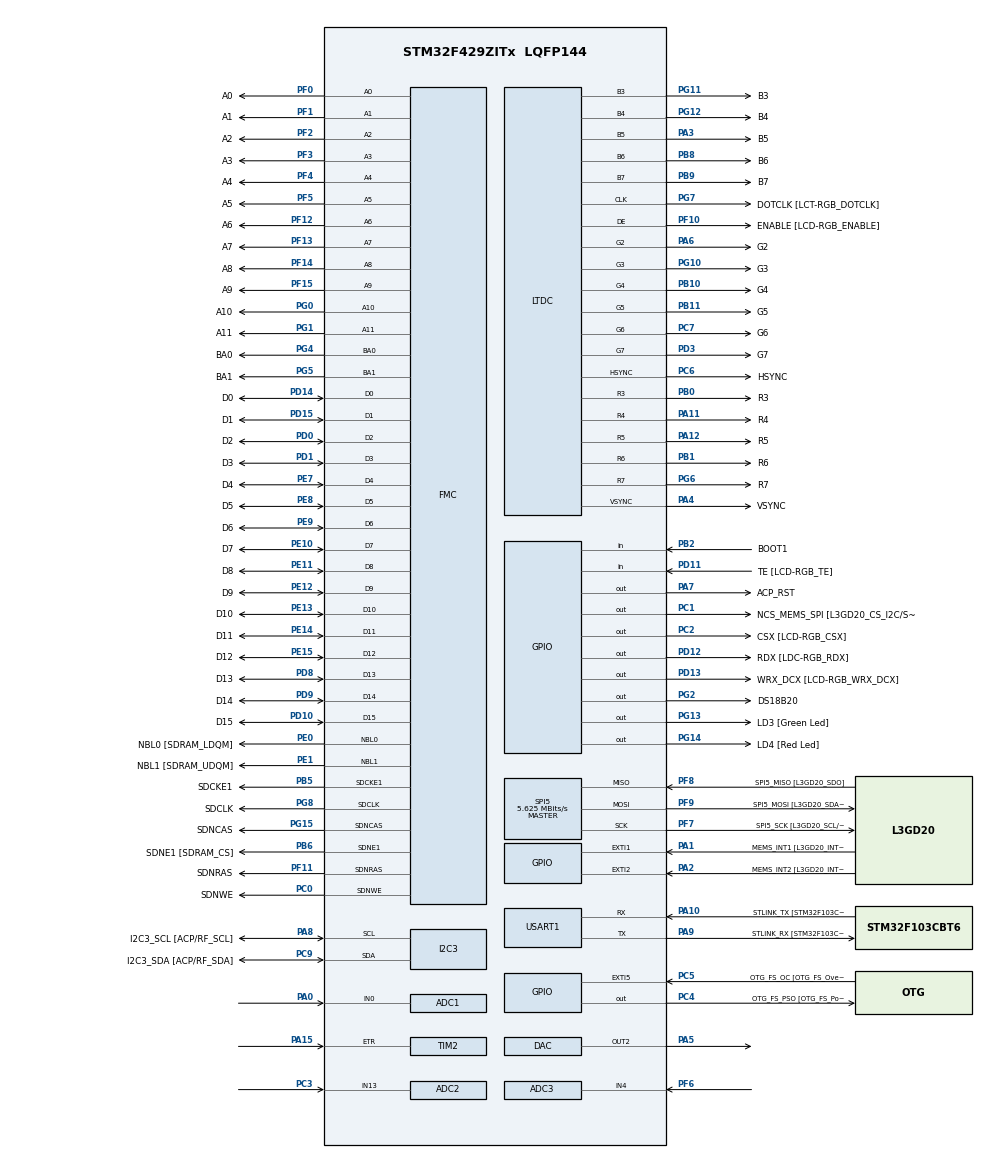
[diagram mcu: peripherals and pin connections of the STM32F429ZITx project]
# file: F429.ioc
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ADC1.Channel-4\#ChannelRegularConversion=ADC_CHANNEL_0
ADC1.ContinuousConvMode=ENABLE
ADC1.Mode=ADC_DUALMODE_REGSIMULT
ADC1.NbrOfConversionFlag=1
ADC1.Rank-4\#ChannelRegularConversion=1
ADC1.SamplingTime-4\#ChannelRegularConversion=ADC_SAMPLETIME_3CYCLES
ADC1.master=1
ADC2.Channel-0\#ChannelRegularConversion=ADC_CHANNEL_13
ADC2.DMAAccessMode=ADC_DMAACCESSMODE_2
ADC2.Mode=ADC_DUALMODE_REGSIMULT
ADC2.NbrOfConversionFlag=1
ADC2.Rank-0\#ChannelRegularConversion=1
ADC2.SamplingTime-0\#ChannelRegularConversion=ADC_SAMPLETIME_3CYCLES
ADC3.Channel-1\#ChannelRegularConversion=ADC_CHANNEL_4
ADC3.DMAAccessMode=ADC_DMAACCESSMODE_2
ADC3.Mode=ADC_DUALMODE_REGSIMULT
ADC3.NbrOfConversionFlag=1
ADC3.Rank-1\#ChannelRegularConversion=1
ADC3.SamplingTime-1\#ChannelRegularConversion=ADC_SAMPLETIME_3CYCLES
DAC.DAC_Trigger2=DAC_TRIGGER_T7_TRGO
Dma.ADC1.1.Direction=DMA_PERIPH_TO_MEMORY
Dma.ADC1.1.FIFOMode=DMA_FIFOMODE_ENABLE
Dma.ADC1.1.FIFOThreshold=DMA_FIFO_THRESHOLD_3QUARTERSFULL
Dma.ADC1.1.Instance=DMA2_Stream0
Dma.ADC1.1.MemBurst=DMA_MBURST_SINGLE
Dma.ADC1.1.MemDataAlignment=DMA_MDATAALIGN_HALFWORD
Dma.ADC1.1.MemInc=DMA_MINC_ENABLE
Dma.ADC1.1.Mode=DMA_NORMAL
Dma.ADC1.1.PeriphBurst=DMA_PBURST_SINGLE
Dma.ADC1.1.PeriphDataAlignment=DMA_PDATAALIGN_HALFWORD
Dma.ADC1.1.PeriphInc=DMA_PINC_DISABLE
Dma.ADC1.1.Priority=DMA_PRIORITY_LOW
Dma.DAC2.0.Direction=DMA_MEMORY_TO_PERIPH
Dma.DAC2.0.FIFOMode=DMA_FIFOMODE_ENABLE
Dma.DAC2.0.FIFOThreshold=DMA_FIFO_THRESHOLD_3QUARTERSFULL
Dma.DAC2.0.Instance=DMA1_Stream6
Dma.DAC2.0.MemBurst=DMA_MBURST_SINGLE
Dma.DAC2.0.MemDataAlignment=DMA_MDATAALIGN_HALFWORD
Dma.DAC2.0.MemInc=DMA_MINC_ENABLE
Dma.DAC2.0.Mode=DMA_CIRCULAR
Dma.DAC2.0.PeriphBurst=DMA_PBURST_SINGLE
Dma.DAC2.0.PeriphDataAlignment=DMA_PDATAALIGN_HALFWORD
Dma.DAC2.0.PeriphInc=DMA_PINC_DISABLE
Dma.DAC2.0.Priority=DMA_PRIORITY_LOW
Dma.Request0=DAC2
Dma.Request1=ADC1
FMC.CASLatency1=FMC_SDRAM_CAS_LATENCY_3
FMC.ExitSelfRefreshDelay1=7
FMC.LoadToActiveDelay1=2
FMC.RCDDelay1=2
FMC.RPDelay1=2
FMC.RPDelay2=2
FMC.ReadBurst1=FMC_SDRAM_RBURST_DISABLE
FMC.ReadPipeDelay1=FMC_SDRAM_RPIPE_DELAY_1
FMC.ReadPipeDelay2=FMC_SDRAM_RPIPE_DELAY_1
FMC.RowCycleDelay1=7
FMC.RowCycleDelay2=7
FMC.SDClockPeriod1=FMC_SDRAM_CLOCK_PERIOD_2
FMC.SDClockPeriod2=FMC_SDRAM_CLOCK_PERIOD_2
FMC.SelfRefreshTime1=4
FMC.WriteRecoveryTime1=3
FREERTOS.Queues01=queFrame,1,uint16_t,0,Dynamic,NULL,NULL;queFreqCount,1,uint32_t,0,Dynamic,NULL,NULL;queTouch,1,uint16_t,0,Dynamic,NULL,NULL;queInfo,16,uint32_t,0,Dynamic,NULL,NULL
FREERTOS.Tasks01=tskIdel,-2,128,fnIdel,Default,NULL,Dynamic,NULL,NULL;tskDisplay,0,1024,fnDisplay,Default,NULL,Dynamic,NULL,NULL;tskTemperature,-2,128,fnTemperature,Default,NULL,Dynamic,NULL,NULL;tskTouch,1,128,fnTouch,Default,NULL,Dynamic,NULL,NULL;tskDAC,-1,256,fnDAC,Default,NULL,Dynamic,NULL,NULL;tskFFT,2,4096,fnFFT,Default,NULL,Dynamic,NULL,NULL
FREERTOS.Timers01=timKeyDown,cbKeyDown,osTimerOnce,Default,NULL,Dynamic,NULL
FREERTOS.configCHECK_FOR_STACK_OVERFLOW=2
FREERTOS.configTOTAL_HEAP_SIZE=128000
FREERTOS.configUSE_APPLICATION_TASK_TAG=1
FREERTOS.configUSE_COUNTING_SEMAPHORES=1
FREERTOS.configUSE_IDLE_HOOK=1
FREERTOS.configUSE_MALLOC_FAILED_HOOK=1
FREERTOS.configUSE_RECURSIVE_MUTEXES=1
FREERTOS.configUSE_TIMERS=1
LTDC.ActiveH=320
LTDC.ActiveW=240
LTDC.Alpha_L0=255
LTDC.BlendingFactor1_L0=LTDC_BLENDING_FACTOR1_PAxCA
LTDC.BlendingFactor2_L0=LTDC_BLENDING_FACTOR2_PAxCA
LTDC.FBStartAdress_L0=0xD0000000
LTDC.HBP=20
LTDC.HFP=10
LTDC.HSync=10
LTDC.ImageHeight_L0=320
LTDC.ImageWidth_L0=240
LTDC.Layers=0
LTDC.PixelFormat_L0=LTDC_PIXEL_FORMAT_RGB565
LTDC.VFP=4
LTDC.VSync=2
LTDC.WindowX1_L0=240
LTDC.WindowY1_L0=320
Mcu.Family=STM32F4
Mcu.Name=STM32F429ZITx
Mcu.Package=LQFP144
NVIC.DMA1_Stream6_IRQn=true\:5\:0\:false\:false\:true\:true\:false\:true
NVIC.DMA2D_IRQn=true\:5\:0\:true\:false\:true\:true\:true\:true
NVIC.DMA2_Stream0_IRQn=true\:5\:0\:false\:false\:true\:true\:false\:true
NVIC.LTDC_IRQn=true\:5\:0\:true\:false\:true\:true\:true\:true
NVIC.PriorityGroup=NVIC_PRIORITYGROUP_4
NVIC.TIM1_UP_TIM10_IRQn=true\:5\:0\:false\:false\:true\:true\:true\:true
NVIC.TIM4_IRQn=true\:5\:0\:false\:false\:true\:true\:true\:true
NVIC.TIM5_IRQn=true\:5\:0\:false\:false\:true\:true\:true\:true
NVIC.TIM6_DAC_IRQn=true\:0\:0\:false\:false\:true\:false\:false\:true
NVIC.TimeBase=TIM6_DAC_IRQn
NVIC.TimeBaseIP=TIM6
PA0/WKUP.Signal=ADCx_IN0
PA1.GPIO_Label=MEMS_INT1 [L3GD20_INT1]
PA1.GPIO_ModeDefaultEXTI=GPIO_MODE_EVT_RISING
PA1.GPIO_PuPd=GPIO_NOPULL
PA1.Signal=GPXTI1
PA10.GPIO_Label=STLINK_TX [STM32F103CBT6_PA2]
PA10.Mode=Asynchronous
PA10.Signal=USART1_RX
PA11.GPIO_Label=R4
PA11.GPIO_Mode=GPIO_MODE_AF_PP
PA11.GPIO_PuPd=GPIO_NOPULL
PA11.GPIO_Speed=GPIO_SPEED_FREQ_LOW
PA11.Mode=RGB565
PA11.Signal=LTDC_R4
PA12.GPIO_Label=R5
PA12.GPIO_Mode=GPIO_MODE_AF_PP
PA12.GPIO_PuPd=GPIO_NOPULL
PA12.GPIO_Speed=GPIO_SPEED_FREQ_LOW
PA12.Mode=RGB565
PA12.Signal=LTDC_R5
PA13.GPIO_Label=SWDIO
PA13.Mode=Trace_Asynchronous_SW
PA13.Signal=SYS_JTMS-SWDIO
PA14.GPIO_Label=SWCLK
PA14.Mode=Trace_Asynchronous_SW
PA14.Signal=SYS_JTCK-SWCLK
PA15.Signal=S_TIM2_CH1_ETR
PA2.GPIO_Label=MEMS_INT2 [L3GD20_INT2]
PA2.GPIO_ModeDefaultEXTI=GPIO_MODE_EVT_RISING
PA2.GPIO_PuPd=GPIO_NOPULL
PA2.Signal=GPXTI2
PA3.GPIO_Label=B5
PA3.GPIO_Mode=GPIO_MODE_AF_PP
PA3.GPIO_PuPd=GPIO_NOPULL
PA3.GPIO_Speed=GPIO_SPEED_FREQ_LOW
PA3.Mode=RGB565
PA3.Signal=LTDC_B5
PA4.GPIO_Label=VSYNC
PA4.GPIO_Mode=GPIO_MODE_AF_PP
PA4.GPIO_PuPd=GPIO_NOPULL
PA4.GPIO_Speed=GPIO_SPEED_FREQ_LOW
PA4.Mode=RGB565
PA4.Signal=LTDC_VSYNC
PA5.Signal=COMP_DAC2_group
PA6.GPIO_Label=G2
PA6.GPIO_Mode=GPIO_MODE_AF_PP
PA6.GPIO_PuPd=GPIO_NOPULL
PA6.GPIO_Speed=GPIO_SPEED_FREQ_LOW
PA6.Mode=RGB565
PA6.Signal=LTDC_G2
PA7.GPIO_Label=ACP_RST
PA7.GPIO_Mode=GPIO_MODE_OUTPUT_PP
PA7.GPIO_PuPd=GPIO_NOPULL
PA7.GPIO_Speed=GPIO_SPEED_FREQ_LOW
PA7.Signal=GPIO_Output
PA8.GPIO_Label=I2C3_SCL [ACP/RF_SCL]
PA8.GPIO_Mode=GPIO_MODE_AF_OD
PA8.GPIO_PuPd=GPIO_NOPULL
PA8.GPIO_Speed=GPIO_SPEED_FREQ_LOW
PA8.Mode=I2C
PA8.Signal=I2C3_SCL
PA9.GPIO_Label=STLINK_RX [STM32F103CBT6_PA3]
PA9.Mode=Asynchronous
PA9.Signal=USART1_TX
PB0.GPIO_Label=R3
PB0.GPIO_Mode=GPIO_MODE_AF_PP
PB0.GPIO_PuPd=GPIO_NOPULL
PB0.GPIO_Speed=GPIO_SPEED_FREQ_LOW
PB0.Mode=RGB565
PB0.Signal=LTDC_R3
PB1.GPIO_Label=R6
PB1.GPIO_Mode=GPIO_MODE_AF_PP
PB1.GPIO_PuPd=GPIO_NOPULL
PB1.GPIO_Speed=GPIO_SPEED_FREQ_LOW
PB1.Mode=RGB565
PB1.Signal=LTDC_R6
PB10.GPIO_Label=G4
PB10.GPIO_Mode=GPIO_MODE_AF_PP
PB10.GPIO_PuPd=GPIO_NOPULL
PB10.GPIO_Speed=GPIO_SPEED_FREQ_LOW
PB10.Mode=RGB565
PB10.Signal=LTDC_G4
PB11.GPIO_Label=G5
PB11.GPIO_Mode=GPIO_MODE_AF_PP
PB11.GPIO_PuPd=GPIO_NOPULL
PB11.GPIO_Speed=GPIO_SPEED_FREQ_LOW
PB11.Mode=RGB565
PB11.Signal=LTDC_G5
PB2/BOOT1.GPIO_Label=BOOT1
PB2/BOOT1.GPIO_Mode=GPIO_MODE_INPUT
PB2/BOOT1.GPIO_PuPd=GPIO_NOPULL
PB2/BOOT1.Signal=GPIO_Input
PB3.Mode=Trace_Asynchronous_SW
PB3.Signal=SYS_JTDO-SWO
PB5.GPIO_Label=SDCKE1
PB5.GPIO_Mode=GPIO_MODE_AF_PP
PB5.GPIO_PuPd=GPIO_NOPULL
PB5.GPIO_Speed=GPIO_SPEED_FREQ_VERY_HIGH
PB5.Mode=SdramChipSelect2_1
PB5.Signal=FMC_SDCKE1
PB6.GPIO_Label=SDNE1 [SDRAM_CS]
PB6.GPIO_Mode=GPIO_MODE_AF_PP
PB6.GPIO_PuPd=GPIO_NOPULL
PB6.GPIO_Speed=GPIO_SPEED_FREQ_VERY_HIGH
PB6.Mode=SdramChipSelect2_1
PB6.Signal=FMC_SDNE1
PB8.GPIO_Label=B6
PB8.GPIO_Mode=GPIO_MODE_AF_PP
PB8.GPIO_PuPd=GPIO_NOPULL
PB8.GPIO_Speed=GPIO_SPEED_FREQ_LOW
PB8.Mode=RGB565
PB8.Signal=LTDC_B6
PB9.GPIO_Label=B7
PB9.GPIO_Mode=GPIO_MODE_AF_PP
PB9.GPIO_PuPd=GPIO_NOPULL
PB9.GPIO_Speed=GPIO_SPEED_FREQ_LOW
PB9.Mode=RGB565
PB9.Signal=LTDC_B7
PC0.GPIO_Label=SDNWE
PC0.GPIO_Mode=GPIO_MODE_AF_PP
PC0.GPIO_PuPd=GPIO_NOPULL
PC0.GPIO_Speed=GPIO_SPEED_FREQ_VERY_HIGH
PC0.Signal=FMC_SDNWE
PC1.GPIO_Label=NCS_MEMS_SPI [L3GD20_CS_I2C/SPI]
PC1.GPIO_Mode=GPIO_MODE_OUTPUT_PP
PC1.GPIO_PuPd=GPIO_NOPULL
PC1.GPIO_Speed=GPIO_SPEED_FREQ_LOW
PC1.Signal=GPIO_Output
PC10.GPIO_Label=R2
PC10.GPIO_Mode=GPIO_MODE_AF_PP
PC10.GPIO_PuPd=GPIO_NOPULL
PC10.GPIO_Speed=GPIO_SPEED_FREQ_LOW
PC10.Signal=LTDC_R2
PC2.GPIO_Label=CSX [LCD-RGB_CSX]
PC2.GPIO_Mode=GPIO_MODE_OUTPUT_PP
PC2.GPIO_PuPd=GPIO_NOPULL
PC2.GPIO_Speed=GPIO_SPEED_FREQ_LOW
PC2.Signal=GPIO_Output
PC3.Signal=ADCx_IN13
PC4.GPIO_Label=OTG_FS_PSO [OTG_FS_PowerSwitchOn]
PC4.GPIO_Mode=GPIO_MODE_OUTPUT_PP
PC4.GPIO_PuPd=GPIO_NOPULL
PC4.GPIO_Speed=GPIO_SPEED_FREQ_LOW
PC4.Signal=GPIO_Output
PC5.GPIO_Label=OTG_FS_OC [OTG_FS_OverCurrent]
PC5.GPIO_ModeDefaultEXTI=GPIO_MODE_EVT_RISING
PC5.Signal=GPXTI5
PC6.GPIO_Label=HSYNC
PC6.GPIO_Mode=GPIO_MODE_AF_PP
PC6.GPIO_PuPd=GPIO_NOPULL
PC6.GPIO_Speed=GPIO_SPEED_FREQ_LOW
PC6.Mode=RGB565
PC6.Signal=LTDC_HSYNC
PC7.GPIO_Label=G6
PC7.GPIO_Mode=GPIO_MODE_AF_PP
PC7.GPIO_PuPd=GPIO_NOPULL
PC7.GPIO_Speed=GPIO_SPEED_FREQ_LOW
PC7.Mode=RGB565
PC7.Signal=LTDC_G6
PC9.GPIO_Label=I2C3_SDA [ACP/RF_SDA]
PC9.GPIO_Mode=GPIO_MODE_AF_OD
PC9.GPIO_PuPd=GPIO_NOPULL
PC9.GPIO_Speed=GPIO_SPEED_FREQ_LOW
PC9.Mode=I2C
PC9.Signal=I2C3_SDA
PD0.GPIO_Label=D2
PD0.GPIO_Mode=GPIO_MODE_AF_PP
PD0.GPIO_PuPd=GPIO_NOPULL
PD0.GPIO_Speed=GPIO_SPEED_FREQ_VERY_HIGH
PD0.Signal=FMC_D2_DA2
PD1.GPIO_Label=D3
PD1.GPIO_Mode=GPIO_MODE_AF_PP
PD1.GPIO_PuPd=GPIO_NOPULL
PD1.GPIO_Speed=GPIO_SPEED_FREQ_VERY_HIGH
PD1.Signal=FMC_D3_DA3
PD10.GPIO_Label=D15
PD10.GPIO_Mode=GPIO_MODE_AF_PP
PD10.GPIO_PuPd=GPIO_NOPULL
PD10.GPIO_Speed=GPIO_SPEED_FREQ_VERY_HIGH
PD10.Signal=FMC_D15_DA15
PD11.GPIO_Label=TE [LCD-RGB_TE]
PD11.GPIO_Mode=GPIO_MODE_INPUT
PD11.GPIO_PuPd=GPIO_NOPULL
PD11.Signal=GPIO_Input
PD12.GPIO_Label=RDX [LDC-RGB_RDX]
PD12.GPIO_Mode=GPIO_MODE_OUTPUT_PP
PD12.GPIO_PuPd=GPIO_NOPULL
PD12.GPIO_Speed=GPIO_SPEED_FREQ_LOW
PD12.Signal=GPIO_Output
PD13.GPIO_Label=WRX_DCX [LCD-RGB_WRX_DCX]
PD13.GPIO_Mode=GPIO_MODE_OUTPUT_PP
PD13.GPIO_PuPd=GPIO_NOPULL
PD13.GPIO_Speed=GPIO_SPEED_FREQ_LOW
PD13.Signal=GPIO_Output
PD14.GPIO_Label=D0
PD14.GPIO_Mode=GPIO_MODE_AF_PP
PD14.GPIO_PuPd=GPIO_NOPULL
PD14.GPIO_Speed=GPIO_SPEED_FREQ_VERY_HIGH
PD14.Signal=FMC_D0_DA0
PD15.GPIO_Label=D1
PD15.GPIO_Mode=GPIO_MODE_AF_PP
PD15.GPIO_PuPd=GPIO_NOPULL
PD15.GPIO_Speed=GPIO_SPEED_FREQ_VERY_HIGH
PD15.Signal=FMC_D1_DA1
PD3.GPIO_Label=G7
PD3.GPIO_Mode=GPIO_MODE_AF_PP
PD3.GPIO_PuPd=GPIO_NOPULL
PD3.GPIO_Speed=GPIO_SPEED_FREQ_LOW
PD3.Mode=RGB565
PD3.Signal=LTDC_G7
PD6.GPIO_Label=B2
PD6.GPIO_Mode=GPIO_MODE_AF_PP
PD6.GPIO_PuPd=GPIO_NOPULL
PD6.GPIO_Speed=GPIO_SPEED_FREQ_LOW
PD6.Signal=LTDC_B2
PD8.GPIO_Label=D13
PD8.GPIO_Mode=GPIO_MODE_AF_PP
PD8.GPIO_PuPd=GPIO_NOPULL
PD8.GPIO_Speed=GPIO_SPEED_FREQ_VERY_HIGH
PD8.Signal=FMC_D13_DA13
PD9.GPIO_Label=D14
PD9.GPIO_Mode=GPIO_MODE_AF_PP
PD9.GPIO_PuPd=GPIO_NOPULL
PD9.GPIO_Speed=GPIO_SPEED_FREQ_VERY_HIGH
PD9.Signal=FMC_D14_DA14
PE0.GPIO_Label=NBL0 [SDRAM_LDQM]
PE0.GPIO_Mode=GPIO_MODE_AF_PP
PE0.GPIO_PuPd=GPIO_NOPULL
PE0.GPIO_Speed=GPIO_SPEED_FREQ_VERY_HIGH
PE0.Signal=FMC_NBL0
PE1.GPIO_Label=NBL1 [SDRAM_UDQM]
PE1.GPIO_Mode=GPIO_MODE_AF_PP
PE1.GPIO_PuPd=GPIO_NOPULL
PE1.GPIO_Speed=GPIO_SPEED_FREQ_VERY_HIGH
PE1.Signal=FMC_NBL1
PE10.GPIO_Label=D7
PE10.GPIO_Mode=GPIO_MODE_AF_PP
PE10.GPIO_PuPd=GPIO_NOPULL
PE10.GPIO_Speed=GPIO_SPEED_FREQ_VERY_HIGH
PE10.Signal=FMC_D7_DA7
PE11.GPIO_Label=D8
PE11.GPIO_Mode=GPIO_MODE_AF_PP
PE11.GPIO_PuPd=GPIO_NOPULL
PE11.GPIO_Speed=GPIO_SPEED_FREQ_VERY_HIGH
PE11.Signal=FMC_D8_DA8
PE12.GPIO_Label=D9
PE12.GPIO_Mode=GPIO_MODE_AF_PP
PE12.GPIO_PuPd=GPIO_NOPULL
PE12.GPIO_Speed=GPIO_SPEED_FREQ_VERY_HIGH
PE12.Signal=FMC_D9_DA9
PE13.GPIO_Label=D10
PE13.GPIO_Mode=GPIO_MODE_AF_PP
PE13.GPIO_PuPd=GPIO_NOPULL
PE13.GPIO_Speed=GPIO_SPEED_FREQ_VERY_HIGH
PE13.Signal=FMC_D10_DA10
PE14.GPIO_Label=D11
PE14.GPIO_Mode=GPIO_MODE_AF_PP
PE14.GPIO_PuPd=GPIO_NOPULL
PE14.GPIO_Speed=GPIO_SPEED_FREQ_VERY_HIGH
PE14.Signal=FMC_D11_DA11
PE15.GPIO_Label=D12
PE15.GPIO_Mode=GPIO_MODE_AF_PP
PE15.GPIO_PuPd=GPIO_NOPULL
PE15.GPIO_Speed=GPIO_SPEED_FREQ_VERY_HIGH
PE15.Signal=FMC_D12_DA12
PE7.GPIO_Label=D4
PE7.GPIO_Mode=GPIO_MODE_AF_PP
PE7.GPIO_PuPd=GPIO_NOPULL
PE7.GPIO_Speed=GPIO_SPEED_FREQ_VERY_HIGH
PE7.Signal=FMC_D4_DA4
PE8.GPIO_Label=D5
PE8.GPIO_Mode=GPIO_MODE_AF_PP
PE8.GPIO_PuPd=GPIO_NOPULL
PE8.GPIO_Speed=GPIO_SPEED_FREQ_VERY_HIGH
PE8.Signal=FMC_D5_DA5
PE9.GPIO_Label=D6
PE9.GPIO_Mode=GPIO_MODE_AF_PP
PE9.GPIO_PuPd=GPIO_NOPULL
PE9.GPIO_Speed=GPIO_SPEED_FREQ_VERY_HIGH
PE9.Signal=FMC_D6_DA6
PF0.GPIO_Label=A0
PF0.GPIO_Mode=GPIO_MODE_AF_PP
PF0.GPIO_PuPd=GPIO_NOPULL
PF0.GPIO_Speed=GPIO_SPEED_FREQ_VERY_HIGH
PF0.Signal=FMC_A0
PF1.GPIO_Label=A1
PF1.GPIO_Mode=GPIO_MODE_AF_PP
PF1.GPIO_PuPd=GPIO_NOPULL
PF1.GPIO_Speed=GPIO_SPEED_FREQ_VERY_HIGH
PF1.Signal=FMC_A1
PF10.GPIO_Label=ENABLE [LCD-RGB_ENABLE]
PF10.GPIO_Mode=GPIO_MODE_AF_PP
PF10.GPIO_PuPd=GPIO_NOPULL
PF10.GPIO_Speed=GPIO_SPEED_FREQ_LOW
PF10.Mode=RGB565
PF10.Signal=LTDC_DE
PF11.GPIO_Label=SDNRAS
PF11.GPIO_Mode=GPIO_MODE_AF_PP
PF11.GPIO_PuPd=GPIO_NOPULL
PF11.GPIO_Speed=GPIO_SPEED_FREQ_VERY_HIGH
PF11.Signal=FMC_SDNRAS
PF12.GPIO_Label=A6
PF12.GPIO_Mode=GPIO_MODE_AF_PP
PF12.GPIO_PuPd=GPIO_NOPULL
PF12.GPIO_Speed=GPIO_SPEED_FREQ_VERY_HIGH
PF12.Signal=FMC_A6
PF13.GPIO_Label=A7
PF13.GPIO_Mode=GPIO_MODE_AF_PP
PF13.GPIO_PuPd=GPIO_NOPULL
PF13.GPIO_Speed=GPIO_SPEED_FREQ_VERY_HIGH
PF13.Signal=FMC_A7
PF14.GPIO_Label=A8
PF14.GPIO_Mode=GPIO_MODE_AF_PP
PF14.GPIO_PuPd=GPIO_NOPULL
PF14.GPIO_Speed=GPIO_SPEED_FREQ_VERY_HIGH
PF14.Signal=FMC_A8
PF15.GPIO_Label=A9
PF15.GPIO_Mode=GPIO_MODE_AF_PP
PF15.GPIO_PuPd=GPIO_NOPULL
PF15.GPIO_Speed=GPIO_SPEED_FREQ_VERY_HIGH
PF15.Signal=FMC_A9
PF2.GPIO_Label=A2
PF2.GPIO_Mode=GPIO_MODE_AF_PP
PF2.GPIO_PuPd=GPIO_NOPULL
PF2.GPIO_Speed=GPIO_SPEED_FREQ_VERY_HIGH
PF2.Signal=FMC_A2
PF3.GPIO_Label=A3
PF3.GPIO_Mode=GPIO_MODE_AF_PP
PF3.GPIO_PuPd=GPIO_NOPULL
PF3.GPIO_Speed=GPIO_SPEED_FREQ_VERY_HIGH
PF3.Signal=FMC_A3
PF4.GPIO_Label=A4
PF4.GPIO_Mode=GPIO_MODE_AF_PP
PF4.GPIO_PuPd=GPIO_NOPULL
PF4.GPIO_Speed=GPIO_SPEED_FREQ_VERY_HIGH
PF4.Signal=FMC_A4
PF5.GPIO_Label=A5
PF5.GPIO_Mode=GPIO_MODE_AF_PP
PF5.GPIO_PuPd=GPIO_NOPULL
PF5.GPIO_Speed=GPIO_SPEED_FREQ_VERY_HIGH
PF5.Signal=FMC_A5
PF6.Mode=IN4
PF6.Signal=ADC3_IN4
PF7.GPIO_Label=SPI5_SCK [L3GD20_SCL/SPC]
PF7.GPIO_Mode=GPIO_MODE_AF_PP
PF7.GPIO_PuPd=GPIO_NOPULL
PF7.GPIO_Speed=GPIO_SPEED_FREQ_LOW
PF7.Mode=Full_Duplex_Master
PF7.Signal=SPI5_SCK
PF8.GPIO_Label=SPI5_MISO [L3GD20_SDO]
PF8.GPIO_Mode=GPIO_MODE_AF_PP
PF8.GPIO_PuPd=GPIO_NOPULL
PF8.GPIO_Speed=GPIO_SPEED_FREQ_LOW
PF8.Mode=Full_Duplex_Master
PF8.Signal=SPI5_MISO
PF9.GPIO_Label=SPI5_MOSI [L3GD20_SDA/SDI/SDO]
PF9.GPIO_Mode=GPIO_MODE_AF_PP
PF9.GPIO_PuPd=GPIO_NOPULL
PF9.GPIO_Speed=GPIO_SPEED_FREQ_LOW
PF9.Mode=Full_Duplex_Master
PF9.Signal=SPI5_MOSI
PG0.GPIO_Label=A10
PG0.GPIO_Mode=GPIO_MODE_AF_PP
PG0.GPIO_PuPd=GPIO_NOPULL
PG0.GPIO_Speed=GPIO_SPEED_FREQ_VERY_HIGH
PG0.Signal=FMC_A10
PG1.GPIO_Label=A11
PG1.GPIO_Mode=GPIO_MODE_AF_PP
PG1.GPIO_PuPd=GPIO_NOPULL
PG1.GPIO_Speed=GPIO_SPEED_FREQ_VERY_HIGH
PG1.Signal=FMC_A11
PG10.GPIO_Label=G3
PG10.GPIO_Mode=GPIO_MODE_AF_PP
PG10.GPIO_PuPd=GPIO_NOPULL
PG10.GPIO_Speed=GPIO_SPEED_FREQ_LOW
PG10.Mode=RGB565
PG10.Signal=LTDC_G3
PG11.GPIO_Label=B3
PG11.GPIO_Mode=GPIO_MODE_AF_PP
PG11.GPIO_PuPd=GPIO_NOPULL
PG11.GPIO_Speed=GPIO_SPEED_FREQ_LOW
PG11.Mode=RGB565
PG11.Signal=LTDC_B3
PG12.GPIO_Label=B4
PG12.GPIO_Mode=GPIO_MODE_AF_PP
PG12.GPIO_PuPd=GPIO_NOPULL
PG12.GPIO_Speed=GPIO_SPEED_FREQ_LOW
PG12.Mode=RGB565
PG12.Signal=LTDC_B4
PG13.GPIO_Label=LD3 [Green Led]
PG13.GPIO_Mode=GPIO_MODE_OUTPUT_PP
PG13.GPIO_PuPd=GPIO_NOPULL
PG13.GPIO_Speed=GPIO_SPEED_FREQ_LOW
PG13.Signal=GPIO_Output
PG14.GPIO_Label=LD4 [Red Led]
PG14.GPIO_Mode=GPIO_MODE_OUTPUT_PP
PG14.GPIO_PuPd=GPIO_NOPULL
PG14.GPIO_Speed=GPIO_SPEED_FREQ_LOW
PG14.Signal=GPIO_Output
PG15.GPIO_Label=SDNCAS
PG15.GPIO_Mode=GPIO_MODE_AF_PP
PG15.GPIO_PuPd=GPIO_NOPULL
PG15.GPIO_Speed=GPIO_SPEED_FREQ_VERY_HIGH
PG15.Signal=FMC_SDNCAS
PG2.GPIO_Label=DS18B20
PG2.GPIO_PuPd=GPIO_PULLUP
PG2.Signal=GPIO_Output
PG4.GPIO_Label=BA0
PG4.GPIO_Mode=GPIO_MODE_AF_PP
PG4.GPIO_PuPd=GPIO_NOPULL
PG4.GPIO_Speed=GPIO_SPEED_FREQ_VERY_HIGH
PG4.Signal=FMC_A14_BA0
PG5.GPIO_Label=BA1
PG5.GPIO_Mode=GPIO_MODE_AF_PP
PG5.GPIO_PuPd=GPIO_NOPULL
PG5.GPIO_Speed=GPIO_SPEED_FREQ_VERY_HIGH
PG5.Signal=FMC_A15_BA1
PG6.GPIO_Label=R7
PG6.GPIO_Mode=GPIO_MODE_AF_PP
PG6.GPIO_PuPd=GPIO_NOPULL
PG6.GPIO_Speed=GPIO_SPEED_FREQ_LOW
PG6.Mode=RGB565
PG6.Signal=LTDC_R7
PG7.GPIO_Label=DOTCLK [LCT-RGB_DOTCLK]
PG7.GPIO_Mode=GPIO_MODE_AF_PP
PG7.GPIO_PuPd=GPIO_NOPULL
PG7.GPIO_Speed=GPIO_SPEED_FREQ_LOW
PG7.Mode=RGB565
PG7.Signal=LTDC_CLK
PG8.GPIO_Label=SDCLK
PG8.GPIO_Mode=GPIO_MODE_AF_PP
PG8.GPIO_PuPd=GPIO_NOPULL
PG8.GPIO_Speed=GPIO_SPEED_FREQ_VERY_HIGH
PG8.Signal=FMC_SDCLK
PH0/OSC_IN.GPIO_Label=PH0-OSC_IN
PH0/OSC_IN.Mode=HSE-External-Oscillator
PH0/OSC_IN.Signal=RCC_OSC_IN
PH1/OSC_OUT.GPIO_Label=PH1-OSC_OUT
PH1/OSC_OUT.Mode=HSE-External-Oscillator
PH1/OSC_OUT.Signal=RCC_OSC_OUT
ProjectManager.HeapSize=0x200
ProjectManager.StackSize=0x400
ProjectManager.TargetToolchain=STM32CubeIDE
RCC.48MHZClocksFreq_Value=120000000
RCC.AHBFreq_Value=180000000
RCC.APB1CLKDivider=RCC_HCLK_DIV4
RCC.APB1Freq_Value=45000000
RCC.APB1TimFreq_Value=90000000
RCC.APB2CLKDivider=RCC_HCLK_DIV2
RCC.APB2Freq_Value=90000000
RCC.APB2TimFreq_Value=180000000
RCC.CortexFreq_Value=180000000
RCC.HCLKFreq_Value=180000000
RCC.HSE_VALUE=8000000
RCC.HSI_VALUE=16000000
RCC.LSE_VALUE=32768
RCC.PLLM=4
RCC.PLLN=180
RCC.PLLQ=3
RCC.PLLSAIDivR=RCC_PLLSAIDIVR_4
RCC.PLLSAIN=60
RCC.PLLSAIR=5
RCC.PLLSourceVirtual=RCC_PLLSOURCE_HSE
RCC.SYSCLKFreq_VALUE=180000000
RCC.SYSCLKSource=RCC_SYSCLKSOURCE_PLLCLK
RCC.VCOOutputFreq_Value=360000000
SH.ADCx_IN0.0=ADC1_IN0,IN0
SH.ADCx_IN13.0=ADC2_IN13,IN13
SH.COMP_DAC2_group.0=DAC_OUT2,DAC_OUT2
SH.FMC_A0.0=FMC_A0,12b-sda1
SH.FMC_A1.0=FMC_A1,12b-sda1
SH.FMC_A10.0=FMC_A10,12b-sda1
SH.FMC_A11.0=FMC_A11,12b-sda1
SH.FMC_A14_BA0.0=FMC_BA0,FourSdramBanks1
SH.FMC_A15_BA1.0=FMC_BA1,FourSdramBanks1
SH.FMC_A2.0=FMC_A2,12b-sda1
SH.FMC_A3.0=FMC_A3,12b-sda1
SH.FMC_A4.0=FMC_A4,12b-sda1
SH.FMC_A5.0=FMC_A5,12b-sda1
SH.FMC_A6.0=FMC_A6,12b-sda1
SH.FMC_A7.0=FMC_A7,12b-sda1
SH.FMC_A8.0=FMC_A8,12b-sda1
SH.FMC_A9.0=FMC_A9,12b-sda1
SH.FMC_D0_DA0.0=FMC_D0,sd-16b-d1
SH.FMC_D10_DA10.0=FMC_D10,sd-16b-d1
SH.FMC_D11_DA11.0=FMC_D11,sd-16b-d1
SH.FMC_D12_DA12.0=FMC_D12,sd-16b-d1
SH.FMC_D13_DA13.0=FMC_D13,sd-16b-d1
SH.FMC_D14_DA14.0=FMC_D14,sd-16b-d1
SH.FMC_D15_DA15.0=FMC_D15,sd-16b-d1
SH.FMC_D1_DA1.0=FMC_D1,sd-16b-d1
SH.FMC_D2_DA2.0=FMC_D2,sd-16b-d1
SH.FMC_D3_DA3.0=FMC_D3,sd-16b-d1
SH.FMC_D4_DA4.0=FMC_D4,sd-16b-d1
SH.FMC_D5_DA5.0=FMC_D5,sd-16b-d1
SH.FMC_D6_DA6.0=FMC_D6,sd-16b-d1
SH.FMC_D7_DA7.0=FMC_D7,sd-16b-d1
SH.FMC_D8_DA8.0=FMC_D8,sd-16b-d1
SH.FMC_D9_DA9.0=FMC_D9,sd-16b-d1
SH.FMC_NBL0.0=FMC_NBL0,Sd2ByteEnable1
SH.FMC_NBL1.0=FMC_NBL1,Sd2ByteEnable1
SH.FMC_SDCLK.0=FMC_SDCLK,12b-sda1
SH.FMC_SDNCAS.0=FMC_SDNCAS,12b-sda1
SH.FMC_SDNRAS.0=FMC_SDNRAS,12b-sda1
SH.FMC_SDNWE.0=FMC_SDNWE,12b-sda1
SH.S_TIM2_CH1_ETR.0=TIM2_ETR,ClockSourceETR_Mode2
SPI5.BaudRatePrescaler=SPI_BAUDRATEPRESCALER_16
SPI5.CalculateBaudRate=5.625 MBits/s
SPI5.Direction=SPI_DIRECTION_2LINES
SPI5.Mode=SPI_MODE_MASTER
SPI5.VirtualType=VM_MASTER
TIM10.Period=29999
TIM10.Prescaler=179
TIM2.AutoReloadPreload=TIM_AUTORELOAD_PRELOAD_ENABLE
TIM2.Period=0xffffffff
TIM2.TIM_MasterOutputTrigger=TIM_TRGO_UPDATE
TIM4.AutoReloadPreload=TIM_AUTORELOAD_PRELOAD_ENABLE
TIM4.Period=39999
TIM4.Prescaler=89
TIM4.TIM_MasterOutputTrigger=TIM_TRGO_UPDATE
TIM5.AutoReloadPreload=TIM_AUTORELOAD_PRELOAD_ENABLE
TIM5.Period=9999
TIM5.Prescaler=8999
TIM5.TIM_MasterOutputTrigger=TIM_TRGO_UPDATE
TIM7.Period=89
TIM7.Prescaler=0
TIM7.TIM_MasterOutputTrigger=TIM_TRGO_UPDATE
USART1.VirtualMode=VM_ASYNC
VP_CRC_VS_CRC.Mode=CRC_Activate
VP_DMA2D_VS_DMA2D.Mode=DMA2D_Activate
VP_FREERTOS_VS_CMSIS_V1.Mode=CMSIS_V1
VP_SYS_VS_tim6.Mode=TIM6
VP_TIM10_VS_ClockSourceINT.Mode=Enable_Timer
VP_TIM1_VS_ClockSourceINT.Mode=Internal
VP_TIM4_VS_ClockSourceINT.Mode=Internal
VP_TIM5_VS_ClockSourceINT.Mode=Internal
VP_TIM7_VS_ClockSourceINT.Mode=Enable_Timer
board=STM32F429I-DISC1

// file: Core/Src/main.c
/* USER CODE BEGIN Header */
/**
  ******************************************************************************
  * @file           : main.c
  * @brief          : Main program body
  ******************************************************************************
  * @attention
  *
  * <h2><center>&copy; Copyright (c) 2020 STMicroelectronics.
  * All rights reserved.</center></h2>
  *
  * This software component is licensed by ST under Ultimate Liberty license
  * SLA0044, the "License"; You may not use this file except in compliance with
  * the License. You may obtain a copy of the License at:
  *                             www.st.com/SLA0044
  *
  ******************************************************************************
  */
/* USER CODE END Header */

#include "main.h"
#include "cmsis_os.h"
#include "adc.h"
#include "crc.h"
#include "dac.h"
#include "dma.h"
#include "dma2d.h"
#include "i2c.h"
#include "ltdc.h"
#include "spi.h"
#include "tim.h"
#include "usart.h"
#include "gpio.h"
#include "fmc.h"

/* USER CODE BEGIN Includes */
#include "../../Board/Inc/board.h"
/* USER CODE END Includes */

/* USER CODE BEGIN PV */
extern osMessageQId queTouchHandle;
/* USER CODE END PV */

void SystemClock_Config(void);
void MX_FREERTOS_Init(void);

int main(void)
{

  /* MCU Configuration--------------------------------------------------------*/

  /* Reset of all peripherals, Initializes the Flash interface and the Systick. */
  HAL_Init();

  /* Configure the system clock */
  SystemClock_Config();

  /* Initialize all configured peripherals */
  MX_GPIO_Init();
  MX_DMA_Init();
  MX_CRC_Init();
  MX_DMA2D_Init();
  MX_FMC_Init();
  MX_I2C3_Init();
  MX_LTDC_Init();
  MX_SPI5_Init();
  MX_TIM1_Init();
  MX_USART1_UART_Init();
  MX_ADC1_Init();
  MX_TIM2_Init();
  MX_TIM4_Init();
  MX_TIM5_Init();
  MX_DAC_Init();
  MX_ADC2_Init();
  MX_ADC3_Init();
  MX_TIM7_Init();
  MX_TIM10_Init();
  /* USER CODE BEGIN 2 */
  board_init(hltdc.LayerCfg[0].FBStartAdress);
  /* USER CODE END 2 */

  /* Call init function for freertos objects (in freertos.c) */
  MX_FREERTOS_Init();
  /* Start scheduler */
  osKernelStart();

  /* We should never get here as control is now taken by the scheduler */
  /* Infinite loop */
  while (1)
  {

  }
}

void SystemClock_Config(void)
{
  LL_FLASH_SetLatency(LL_FLASH_LATENCY_5);

  if(LL_FLASH_GetLatency() != LL_FLASH_LATENCY_5)
  {
  Error_Handler();
  }
  LL_PWR_SetRegulVoltageScaling(LL_PWR_REGU_VOLTAGE_SCALE1);
  LL_PWR_EnableOverDriveMode();
  LL_RCC_HSE_Enable();

   /* Wait till HSE is ready */
  while(LL_RCC_HSE_IsReady() != 1)
  {

  }
  LL_RCC_PLL_ConfigDomain_SYS(LL_RCC_PLLSOURCE_HSE, LL_RCC_PLLM_DIV_4, 180, LL_RCC_PLLP_DIV_2);
  LL_RCC_PLLSAI_ConfigDomain_LTDC(LL_RCC_PLLSOURCE_HSE, LL_RCC_PLLSAIM_DIV_4, 60, LL_RCC_PLLSAIR_DIV_5, LL_RCC_PLLSAIDIVR_DIV_4);
  LL_RCC_PLL_Enable();

   /* Wait till PLL is ready */
  while(LL_RCC_PLL_IsReady() != 1)
  {

  }
  LL_RCC_PLLSAI_Enable();

   /* Wait till PLL is ready */
  while(LL_RCC_PLLSAI_IsReady() != 1)
  {

  }
  LL_RCC_SetAHBPrescaler(LL_RCC_SYSCLK_DIV_1);
  LL_RCC_SetAPB1Prescaler(LL_RCC_APB1_DIV_4);
  LL_RCC_SetAPB2Prescaler(LL_RCC_APB2_DIV_2);
  LL_RCC_SetSysClkSource(LL_RCC_SYS_CLKSOURCE_PLL);

   /* Wait till System clock is ready */
  while(LL_RCC_GetSysClkSource() != LL_RCC_SYS_CLKSOURCE_STATUS_PLL)
  {

  }
  LL_SetSystemCoreClock(180000000);

   /* Update the time base */
  if (HAL_InitTick (TICK_INT_PRIORITY) != HAL_OK)
  {
    Error_Handler();
  };
  LL_RCC_SetTIMPrescaler(LL_RCC_TIM_PRESCALER_TWICE);
}

 /**
  * @brief  Period elapsed callback in non blocking mode
  * @note   This function is called  when TIM6 interrupt took place, inside
  * HAL_TIM_IRQHandler(). It makes a direct call to HAL_IncTick() to increment
  * a global variable "uwTick" used as application time base.
  * @param  htim : TIM handle
  * @retval None
  */
void HAL_TIM_PeriodElapsedCallback(TIM_HandleTypeDef *htim)
{
  if (htim->Instance == TIM6) {
    HAL_IncTick();
  }
  /* USER CODE BEGIN Callback 1 */
	if(htim->Instance == TIM10){
		osMessagePut(queTouchHandle, 0, 0);
		LL_TIM_ClearFlag_UPDATE(TIM10);
	}
  /* USER CODE END Callback 1 */
}

void Error_Handler(void)
{
}

/************************ (C) COPYRIGHT STMicroelectronics *****END OF FILE****/

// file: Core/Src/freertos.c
/* USER CODE BEGIN Header */
/**
 ******************************************************************************
 * File Name          : freertos.c
 * Description        : Code for freertos applications
 ******************************************************************************
 * @attention
 *
 * <h2><center>&copy; Copyright (c) 2020 STMicroelectronics.
 * All rights reserved.</center></h2>
 *
 * This software component is licensed by ST under Ultimate Liberty license
 * SLA0044, the "License"; You may not use this file except in compliance with
 * the License. You may obtain a copy of the License at:
 *                             www.st.com/SLA0044
 *
 ******************************************************************************
 */
/* USER CODE END Header */

#include "FreeRTOS.h"
#include "task.h"
#include "main.h"
#include "cmsis_os.h"

/* USER CODE BEGIN Includes */
#include "tim.h"
#include <stdio.h>
#include <stdlib.h>
#include "../../Board/Inc/board.h"
#include "../../CNSIT/Inc/GRAPHICS.h"
#include "../../CNSIT/Inc/DS18B20.h"
//#include "../../CNSIT/Font/FONT_ENHANCED_DOT_DIGITAL_16PT.h"
//const CNSITFontDescTypeDef* font = &enhancedDotDigital7_16ptDesc;
#include "../../CNSIT/Font/FONT_APPLE_][_12PT.h"
const CNSITFontDescTypeDef* font = &apple_12ptDesc;
/* USER CODE END Includes */

/* USER CODE BEGIN Variables */
__IO uint32_t freq_count;
/* USER CODE END Variables */
osThreadId tskIdelHandle;
osThreadId tskDisplayHandle;
osThreadId tskTemperatureHandle;
osThreadId tskTouchHandle;
osThreadId tskDACHandle;
osThreadId tskFFTHandle;
osMessageQId queFrameHandle;
osMessageQId queFreqCountHandle;
osMessageQId queTouchHandle;
osMessageQId queInfoHandle;
osTimerId timKeyDownHandle;

void fnIdel(void const * argument);
void fnDisplay(void const * argument);
void fnTemperature(void const * argument);
void fnTouch(void const * argument);
void fnDAC(void const * argument);
void fnFFT(void const * argument);
void cbKeyDown(void const * argument);

void MX_FREERTOS_Init(void); /* (MISRA C 2004 rule 8.1) */

/* GetIdleTaskMemory prototype (linked to static allocation support) */
void vApplicationGetIdleTaskMemory( StaticTask_t **ppxIdleTaskTCBBuffer, StackType_t **ppxIdleTaskStackBuffer, uint32_t *pulIdleTaskStackSize );

/* GetTimerTaskMemory prototype (linked to static allocation support) */
void vApplicationGetTimerTaskMemory( StaticTask_t **ppxTimerTaskTCBBuffer, StackType_t **ppxTimerTaskStackBuffer, uint32_t *pulTimerTaskStackSize );

/* Hook prototypes */
void vApplicationIdleHook(void);
void vApplicationStackOverflowHook(xTaskHandle xTask, signed char *pcTaskName);
void vApplicationMallocFailedHook(void);

/* USER CODE BEGIN 2 */
__weak void vApplicationIdleHook( void )
{
	/* vApplicationIdleHook() will only be called if configUSE_IDLE_HOOK is set
   to 1 in FreeRTOSConfig.h. It will be called on each iteration of the idle
   task. It is essential that code added to this hook function never attempts
   to block in any way (for example, call xQueueReceive() with a block time
   specified, or call vTaskDelay()). If the application makes use of the
   vTaskDelete() API function (as this demo application does) then it is also
   important that vApplicationIdleHook() is permitted to return to its calling
   function, because it is the responsibility of the idle task to clean up
   memory allocated by the kernel to any task that has since been deleted. */
}
/* USER CODE END 2 */

/* USER CODE BEGIN 4 */
__weak void vApplicationStackOverflowHook(xTaskHandle xTask, signed char *pcTaskName)
{
	/* Run time stack overflow checking is performed if
   configCHECK_FOR_STACK_OVERFLOW is defined to 1 or 2. This hook function is
   called if a stack overflow is detected. */
}
/* USER CODE END 4 */

/* USER CODE BEGIN 5 */
__weak void vApplicationMallocFailedHook(void)
{
	/* vApplicationMallocFailedHook() will only be called if
   configUSE_MALLOC_FAILED_HOOK is set to 1 in FreeRTOSConfig.h. It is a hook
   function that will get called if a call to pvPortMalloc() fails.
   pvPortMalloc() is called internally by the kernel whenever a task, queue,
   timer or semaphore is created. It is also called by various parts of the
   demo application. If heap_1.c or heap_2.c are used, then the size of the
   heap available to pvPortMalloc() is defined by configTOTAL_HEAP_SIZE in
   FreeRTOSConfig.h, and the xPortGetFreeHeapSize() API function can be used
   to query the size of free heap space that remains (although it does not
   provide information on how the remaining heap might be fragmented). */
}
/* USER CODE END 5 */

/* USER CODE BEGIN GET_IDLE_TASK_MEMORY */
static StaticTask_t xIdleTaskTCBBuffer;
static StackType_t xIdleStack[configMINIMAL_STACK_SIZE];

void vApplicationGetIdleTaskMemory( StaticTask_t **ppxIdleTaskTCBBuffer, StackType_t **ppxIdleTaskStackBuffer, uint32_t *pulIdleTaskStackSize )
{
	*ppxIdleTaskTCBBuffer = &xIdleTaskTCBBuffer;
	*ppxIdleTaskStackBuffer = &xIdleStack[0];
	*pulIdleTaskStackSize = configMINIMAL_STACK_SIZE;
	/* place for user code */
}
/* USER CODE END GET_IDLE_TASK_MEMORY */

/* USER CODE BEGIN GET_TIMER_TASK_MEMORY */
static StaticTask_t xTimerTaskTCBBuffer;
static StackType_t xTimerStack[configTIMER_TASK_STACK_DEPTH];

void vApplicationGetTimerTaskMemory( StaticTask_t **ppxTimerTaskTCBBuffer, StackType_t **ppxTimerTaskStackBuffer, uint32_t *pulTimerTaskStackSize )
{
	*ppxTimerTaskTCBBuffer = &xTimerTaskTCBBuffer;
	*ppxTimerTaskStackBuffer = &xTimerStack[0];
	*pulTimerTaskStackSize = configTIMER_TASK_STACK_DEPTH;
	/* place for user code */
}
/* USER CODE END GET_TIMER_TASK_MEMORY */

void MX_FREERTOS_Init(void) {

	/* Create the timer(s) */
	/* definition and creation of timKeyDown */
	osTimerDef(timKeyDown, cbKeyDown);
	timKeyDownHandle = osTimerCreate(osTimer(timKeyDown), osTimerOnce, NULL);

	/* Create the queue(s) */
	/* definition and creation of queFrame */
	osMessageQDef(queFrame, 1, uint16_t);
	queFrameHandle = osMessageCreate(osMessageQ(queFrame), NULL);

	/* definition and creation of queFreqCount */
	osMessageQDef(queFreqCount, 1, uint32_t);
	queFreqCountHandle = osMessageCreate(osMessageQ(queFreqCount), NULL);

	/* definition and creation of queTouch */
	osMessageQDef(queTouch, 1, uint16_t);
	queTouchHandle = osMessageCreate(osMessageQ(queTouch), NULL);

	/* definition and creation of queInfo */
	osMessageQDef(queInfo, 16, uint32_t);
	queInfoHandle = osMessageCreate(osMessageQ(queInfo), NULL);

	/* Create the thread(s) */
	/* definition and creation of tskIdel */
	osThreadDef(tskIdel, fnIdel, osPriorityLow, 0, 128);
	tskIdelHandle = osThreadCreate(osThread(tskIdel), NULL);

	/* definition and creation of tskDisplay */
	osThreadDef(tskDisplay, fnDisplay, osPriorityAboveNormal, 0, 1024);
	tskDisplayHandle = osThreadCreate(osThread(tskDisplay), NULL);

	/* definition and creation of tskTemperature */
	osThreadDef(tskTemperature, fnTemperature, osPriorityLow, 0, 128);
	tskTemperatureHandle = osThreadCreate(osThread(tskTemperature), NULL);

	/* definition and creation of tskTouch */
	osThreadDef(tskTouch, fnTouch, osPriorityNormal, 0, 128);
	tskTouchHandle = osThreadCreate(osThread(tskTouch), NULL);

	/* definition and creation of tskDAC */
	osThreadDef(tskDAC, fnDAC, osPriorityBelowNormal, 0, 256);
	tskDACHandle = osThreadCreate(osThread(tskDAC), NULL);

	/* definition and creation of tskFFT */
	osThreadDef(tskFFT, fnFFT, osPriorityHigh, 0, 4096);
	tskFFTHandle = osThreadCreate(osThread(tskFFT), NULL);

}

void fnIdel(void const * argument)
{
	/* USER CODE BEGIN fnIdel */
	uint8_t idle_count = 0;
	/* Infinite loop */
	for(;;)
	{
		osDelay(250);
		LL_GPIO_TogglePin(LD3_GPIO_Port, LD3_Pin);
		idle_count ++;
	}
	/* USER CODE END fnIdel */
}

void fnDisplay(void const * argument)
{
	/* USER CODE BEGIN fnDisplay */
	char msg[32];
	uint16_t bg = BLACK, fg = YELLOW;
	lcd.Fill(0, 0, lcd.GetWidth(), lcd.GetHeight(), bg);

	STMPE811Start();
	LL_TIM_EnableIT_UPDATE(TIM10);
	LL_TIM_EnableCounter(TIM10);

	LL_TIM_EnableIT_UPDATE(TIM4);
	LL_TIM_EnableCounter(TIM4);
	LL_TIM_EnableIT_UPDATE(TIM5);
	LL_TIM_EnableCounter(TIM5);
	LL_TIM_EnableExternalClock(TIM2);
	LL_TIM_EnableCounter(TIM2);

	/* Infinite loop */
	for(;;)
	{
		osEvent e = osMessageGet(queFrameHandle, 500);
		if(e.status == osEventMessage){
			//board_demo();

			e = osMessageGet(queInfoHandle,0);
			while(e.status == osEventMessage){
				INFO* info = (INFO*)e.value.p;
				uint16_t x,y;
				if(info->src == TOUCH){
					x = 0;
					y = font->Height;

					sprintf(msg, "%s:%5d", info->data[0].label, *(uint16_t*)info->data[0].value.p);
					x = String(x, y, YELLOW, bg, msg, &lcd, font);
					sprintf(msg, "%s:%5d", info->data[1].label, *(uint16_t*)info->data[1].value.p);
					String(x+20, y, YELLOW, bg, msg, &lcd, font);

					x = 0; y = 0;
					sprintf(msg, "%s:%2x", info->data[3].label, *(uint8_t*)info->data[3].value.p);
					x= String(x, y, fg, bg, msg, &lcd, font);
					sprintf(msg, "%s:%2x", info->data[2].label, *(uint8_t*)info->data[2].value.p);
					String(x + 20, y, fg, bg, msg, &lcd, font);
				}else if(info->src == TEMP){
					float temperature = *(float*)info->data[0].value.p;
					if(temperature>=0){
						sprintf(msg, "%s:+%6.3f'C", info->data[0].label, temperature);
					}else{
						sprintf(msg, "%s:%7.3f'C", info->data[0].label, temperature);
					}
					x = 0;
					y = font->Height<<1;
					String(x, y , RED, bg, msg, &lcd, font);
				}else if(info->src==FC){
					x = 0;
					y = font->Height*3;
					sprintf(msg, "%s:%ld", info->data[0].label, info->data[0].value.v);
					String(x,y, GREEN, bg, msg, &lcd, font);
				}
				e = osMessageGet(queInfoHandle,0);
			}
			LL_GPIO_TogglePin(LD4_GPIO_Port, LD4_Pin);
		}
	}
	/* USER CODE END fnDisplay */
}

void fnTemperature(void const * argument)
{
	/* USER CODE BEGIN fnTemperature */
	float temperature;
	DATUM data[1] = {
		{"Temp", {.p = (float*)&temperature}}
	};
	INFO info = {
		TEMP,
		data
	};
	/* Infinite loop */
	for(;;)
	{
		osDelay(450);
		temperature = DS18B20Convert(DS18B20_GPIO_Port,DS18B20_Pin);
		osMessagePut(queInfoHandle, (uint32_t)&info, 0);
	}
	/* USER CODE END fnTemperature */
}

void fnTouch(void const * argument)
{
	/* USER CODE BEGIN fnTouch */
	uint16_t touch_x=0, touch_y=0;
	uint8_t touch_int, touch_fifo;
	DATUM data[4] = {
		{"X", {.p=(uint32_t*)&touch_x}},
		{"Y", {.p =(uint32_t*)&touch_y}},
		{"INT", {.p=(uint32_t*)&touch_int}},
		{"FIFO", {.p=(uint32_t*)&touch_fifo}}
	};
	INFO info = {
		TOUCH,
		data
	};
	/* Infinite loop */
	for(;;)
	{
		osEvent e = osMessageGet(queTouchHandle, 700);
		if(e.status == osEventMessage){
			touch_int = STMPE811Read(0x0b);
			touch_fifo = STMPE811Read(0x4b);
			osMessagePut(queInfoHandle, (uint32_t)&info, 0);
			STMPE811GetXY(&touch_x, &touch_y, lcd.GetWidth(), lcd.GetHeight());
		}
	}
	/* USER CODE END fnTouch */
}

void fnDAC(void const * argument)
{
	/* USER CODE BEGIN fnDAC */
	/* Infinite loop */
	for(;;)
	{
		osDelay(1000);
	}
	/* USER CODE END fnDAC */
}

void fnFFT(void const * argument)
{
	/* USER CODE BEGIN fnFFT */
	/* Infinite loop */
	for(;;)
	{
		osDelay(1000);
	}
	/* USER CODE END fnFFT */
}

/* cbKeyDown function */
void cbKeyDown(void const * argument)
{
}

/************************ (C) COPYRIGHT STMicroelectronics *****END OF FILE****/
